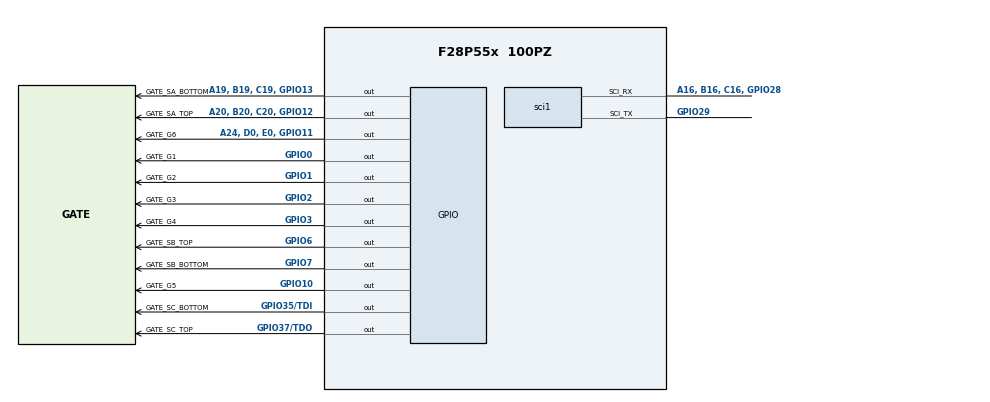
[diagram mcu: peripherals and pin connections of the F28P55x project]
/**
 *
 * @cliArgs --device "F28P55x" --part "F28P55x_100PZ" --package "100PZ" --context "system" --product "C2000WARE@26.01.00.00"
 * @versions {"tool":"1.28.0+4696"}
 */

/**
 * Import the modules used in this configuration.
 */
const adc     = scripting.addModule("/driverlib/adc.js", {}, false);
const adc1    = adc.addInstance();
const analog  = scripting.addModule("/driverlib/analog.js", {}, false);
const analog1 = analog.addInstance();
const asysctl = scripting.addModule("/driverlib/asysctl.js");
const gpio    = scripting.addModule("/driverlib/gpio.js", {}, false);
const gpio1   = gpio.addInstance();
const gpio2   = gpio.addInstance();
const gpio3   = gpio.addInstance();
const gpio4   = gpio.addInstance();
const gpio5   = gpio.addInstance();
const gpio6   = gpio.addInstance();
const gpio7   = gpio.addInstance();
const gpio8   = gpio.addInstance();
const gpio9   = gpio.addInstance();
const gpio10  = gpio.addInstance();
const gpio11  = gpio.addInstance();
const gpio12  = gpio.addInstance();
const sci     = scripting.addModule("/driverlib/sci.js", {}, false);
const sci1    = sci.addInstance();

/**
 * Write custom configuration values to the imported modules.
 */
adc1.$name               = "myADC0";
adc1.adcClockPrescaler   = "ADC_CLK_DIV_2_0";
adc1.enabledSOCs         = ["ADC_SOC_NUMBER0","ADC_SOC_NUMBER1","ADC_SOC_NUMBER2","ADC_SOC_NUMBER3"];
adc1.soc0SampleWindow    = 10;
adc1.soc1Channel         = "ADC_CH_ADCIN4";
adc1.soc1SampleWindow    = 10;
adc1.soc2Channel         = "ADC_CH_ADCIN5";
adc1.soc2SampleWindow    = 10;
adc1.soc3Channel         = "ADC_CH_ADCIN9";
adc1.soc3SampleWindow    = 10;
adc1.interruptPulseMode  = "ADC_PULSE_END_OF_CONV";
adc1.enabledInts         = ["ADC_INT_NUMBER1"];
adc1.enableInterrupt1    = true;
adc1.interrupt1SOCSource = "ADC_INT_TRIGGER_EOC3";

analog1.$name            = "myANALOGPinMux0";
adc1.analog              = analog1;
analog1.useCase          = "CUSTOM";
analog1.useInterfacePins = ["A0, B15, C15, DACA_OUT","A4, B8","A5","A9, GPIO227"];

asysctl.analogReference        = "INTERNAL";
asysctl.analogReferenceVoltage = "1P65";

gpio1.direction         = "GPIO_DIR_MODE_OUT";
gpio1.writeInitialValue = true;
gpio1.$name             = "GATE_G1";
gpio1.gpioPin.$assign   = "GPIO0";

gpio2.direction         = "GPIO_DIR_MODE_OUT";
gpio2.$name             = "GATE_G2";
gpio2.writeInitialValue = true;
gpio2.gpioPin.$assign   = "GPIO1";

gpio3.direction         = "GPIO_DIR_MODE_OUT";
gpio3.$name             = "GATE_G3";
gpio3.writeInitialValue = true;
gpio3.gpioPin.$assign   = "GPIO2";

gpio4.direction         = "GPIO_DIR_MODE_OUT";
gpio4.$name             = "GATE_G4";
gpio4.writeInitialValue = true;
gpio4.gpioPin.$assign   = "GPIO3";

gpio5.direction         = "GPIO_DIR_MODE_OUT";
gpio5.$name             = "GATE_G5";
gpio5.writeInitialValue = true;
gpio5.gpioPin.$assign   = "GPIO10";

gpio6.direction         = "GPIO_DIR_MODE_OUT";
gpio6.$name             = "GATE_G6";
gpio6.writeInitialValue = true;
gpio6.gpioPin.$assign   = "A24, D0, E0, GPIO11";

gpio7.direction         = "GPIO_DIR_MODE_OUT";
gpio7.$name             = "GATE_SA_TOP";
gpio7.writeInitialValue = true;
gpio7.gpioPin.$assign   = "A20, B20, C20, GPIO12";

gpio8.direction         = "GPIO_DIR_MODE_OUT";
gpio8.$name             = "GATE_SA_BOTTOM";
gpio8.writeInitialValue = true;
gpio8.gpioPin.$assign   = "A19, B19, C19, GPIO13";

gpio9.direction         = "GPIO_DIR_MODE_OUT";
gpio9.$name             = "GATE_SB_TOP";
gpio9.writeInitialValue = true;
gpio9.gpioPin.$assign   = "GPIO6";

gpio10.direction         = "GPIO_DIR_MODE_OUT";
gpio10.$name             = "GATE_SB_BOTTOM";
gpio10.writeInitialValue = true;
gpio10.gpioPin.$assign   = "GPIO7";

gpio11.direction         = "GPIO_DIR_MODE_OUT";
gpio11.$name             = "GATE_SC_TOP";
gpio11.writeInitialValue = true;
gpio11.gpioPin.$assign   = "GPIO37/TDO";

gpio12.direction         = "GPIO_DIR_MODE_OUT";
gpio12.$name             = "GATE_SC_BOTTOM";
gpio12.writeInitialValue = true;
gpio12.gpioPin.$assign   = "GPIO35/TDI";

sci1.$name                 = "mySCI0";
sci1.useFifo               = false;
sci1.sci.$assign           = "SCIA";
sci1.sci.sci_rxPin.$assign = "A16, B16, C16, GPIO28";
sci1.sci.sci_txPin.$assign = "GPIO29";
sci1.rxQual.$name          = "myGPIOQUAL0";
sci1.txQual.$name          = "myGPIOQUAL1";

/**
 * Pinmux solution for unlocked pins/peripherals. This ensures that minor changes to the automatic solver in a future
 * version of the tool will not impact the pinmux you originally saw.  These lines can be completely deleted in order to
 * re-solve from scratch.
 */
analog1.analog.$suggestSolution                              = "ANALOG";
analog1.analog["a0, b15, c15, daca_outPin"].$suggestSolution = "A0, B15, C15, DACA_OUT";
analog1.analog["a4, b8Pin"].$suggestSolution                 = "A4, B8";
analog1.analog.a5Pin.$suggestSolution                        = "A5";
analog1.analog["a9, gpio227Pin"].$suggestSolution            = "A9, GPIO227";
